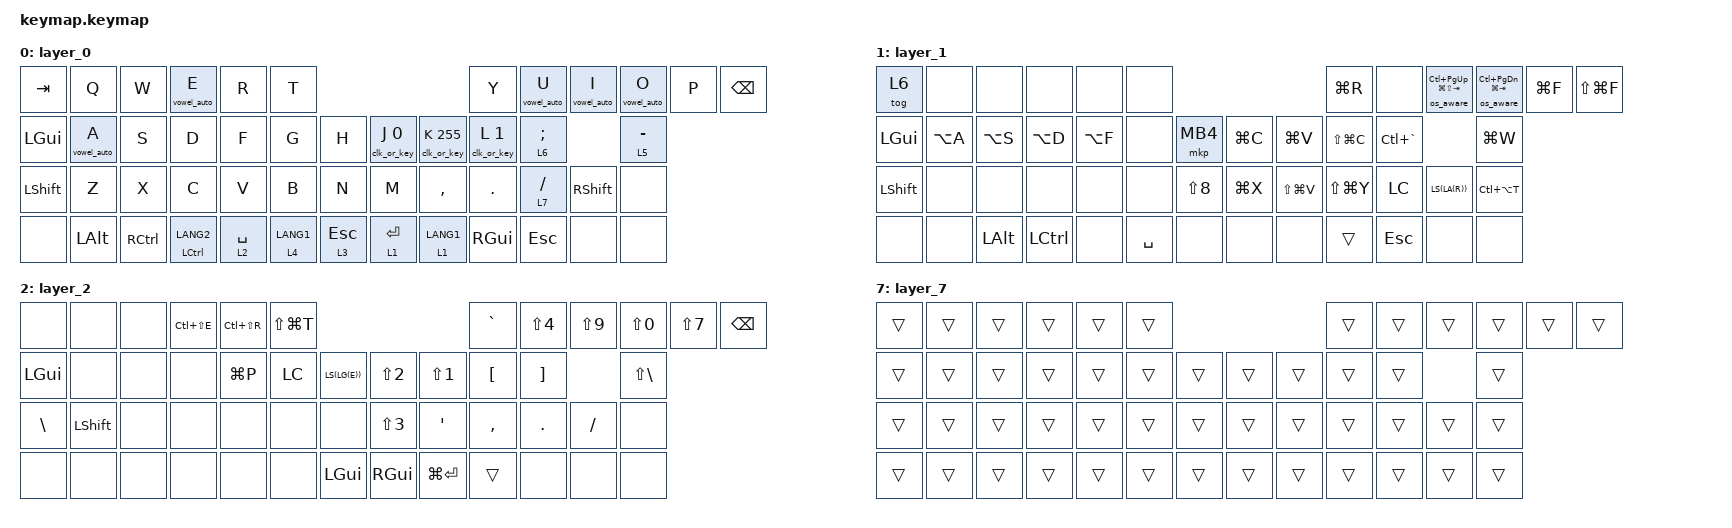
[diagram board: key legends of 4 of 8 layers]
/*
 * Copyright 2026 ren-mntn
 * SPDX-License-Identifier: MIT
 *
 * Ported from Keyball44 Remap keymap (7 layers).
 * Target: torabo-tsuki M variant (50 keys per layer: 12+12+12+14).
 */

#include <behaviors.dtsi>
#include <dt-bindings/zmk/bt.h>
#include <dt-bindings/zmk/keys.h>
#include <dt-bindings/zmk/mouse.h>
#include <dt-bindings/zmk/outputs.h>
#include <dt-bindings/zmk/pointing.h>

/ {
    behaviors {
        clk_or_key: clk_or_key {
            compatible = "zmk,behavior-clk-or-key";
            #binding-cells = <2>;
        };

        bt_toggle_01: bt_toggle_01 {
            compatible = "zmk,behavior-bt-toggle-01";
            #binding-cells = <0>;
        };

        vowel_auto: vowel_auto {
            compatible = "zmk,behavior-vowel-auto";
            #binding-cells = <1>;
        };

        os_aware: os_aware {
            compatible = "zmk,behavior-os-aware";
            #binding-cells = <2>;
        };
    };

    mouse_accel: mouse_accel {
        compatible = "zmk,input-processor-mouse-accel";
        #input-processor-cells = <0>;
    };

    scroll_mode: scroll_mode {
        compatible = "zmk,input-processor-scroll-mode";
        #input-processor-cells = <0>;
    };

    keymap {
        compatible = "zmk,keymap";

        /* Layer 0: Base QWERTY
         * Mouse-mode actions: J=LCLK, K=drag-scroll-trigger (0xFF), L=RCLK
         * Typing-mode fallback: J/K/L letters
         */
        layer_0 {
            bindings = <
&kp TAB    &kp Q      &kp W      &vowel_auto E &kp R      &kp T                                                &kp Y      &vowel_auto U      &vowel_auto I      &vowel_auto O      &kp P              &kp BSPC
&kp LGUI   &vowel_auto A &kp S   &kp D      &kp F      &kp G                                                   &kp H      &clk_or_key J 0  &clk_or_key K 255  &clk_or_key L 1  &lt 6 SEMI         &lt 5 MINUS
&kp LSHFT  &kp Z      &kp X      &kp C      &kp V      &kp B                                                   &kp N      &kp M              &kp COMMA          &kp DOT            &lt 7 FSLH         &kp RSHFT
&none      &none      &kp LALT   &kp RCTRL  &mt LCTRL LANG2  &lt 2 SPACE  &lt 4 LANG1           &lt 3 ESC  &lt 1 RET  &lt 1 LANG1        &kp RGUI           &kp ESC            &none              &none
            >;
        };

        /* Layer 1: Editor shortcuts (Win/Alt combos) */
        layer_1 {
            bindings = <
&tog 6     &none      &none      &none      &none      &none                                                   &kp LG(R)  &none              &os_aware LC(PG_UP) LG(LS(TAB))  &os_aware LC(PG_DN) LG(TAB)  &kp LG(F)          &kp LS(LG(F))
&kp LGUI   &kp LA(A)  &kp LA(S)  &kp LA(D)  &kp LA(F)  &none                                                   &mkp MB4   &kp LG(C)          &kp LG(V)          &kp LS(LG(C))      &kp LC(GRAVE)      &kp LG(W)
&kp LSHFT  &none      &none      &none      &none      &none                                                   &kp LS(N8) &kp LG(X)          &kp LS(LG(V))      &kp LS(LG(Y))      &kp LC(LS(LA(R)))  &kp LC(LA(T))
&none      &none      &kp LALT   &kp LCTRL  &none      &kp SPACE  &none                                 &none      &none              &trans             &kp ESC            &none              &none
            >;
        };

        /* Layer 2: Symbols */
        layer_2 {
            bindings = <
&none      &none      &none      &kp LC(LS(E)) &kp LC(LS(R)) &kp LS(LG(T))                                      &kp GRAVE  &kp LS(N4)         &kp LS(N9)         &kp LS(N0)         &kp LS(N7)         &kp BSPC
&kp LGUI   &none      &none      &none      &kp LG(P)  &kp LC(LS(LG(E)))                                        &kp LS(N2) &kp LS(N1)         &kp LBKT           &kp RBKT           &kp LS(BSLH)       &kp BSLH
&kp LSHFT  &none      &none      &none      &none      &none                                                   &kp LS(N3) &kp SQT            &kp COMMA          &kp DOT            &kp FSLH           &none
&none      &none      &none      &none      &none      &none      &kp LGUI                              &kp RGUI   &kp LG(RET)        &trans             &none              &none              &none
            >;
        };

        /* Layer 3: Neovim navigation (Ctrl combos) */
        layer_3 {
            bindings = <
&none      &none      &none      &none      &none      &none                                                   &none      &none              &none              &none              &none              &kp BSPC
&none      &none      &none      &none      &none      &none                                                   &kp LC(LS(E)) &kp LC(Q)       &kp LC(G)          &kp LC(GRAVE)      &kp LC(LS(GRAVE))  &none
&none      &none      &none      &none      &none      &none                                                   &kp LC(H)  &kp LC(J)          &kp LC(K)          &kp LC(L)          &none              &none
&none      &none      &none      &none      &none      &none      &kp LALT                              &none      &none              &trans             &none              &none              &none
            >;
        };

        /* Layer 4: Numbers */
        layer_4 {
            bindings = <
&none      &none      &none      &none      &none      &none                                                   &kp LS(COMMA) &kp LS(N5)      &kp EQUAL          &kp LS(EQUAL)      &kp LS(N8)         &kp BSPC
&kp LGUI   &none      &none      &none      &none      &none                                                   &kp N1     &kp N2             &kp N3             &kp N4             &kp N5             &kp MINUS
&kp LSHFT  &none      &none      &none      &none      &none                                                   &kp N6     &kp N7             &kp N8             &kp N9             &kp N0             &kp LS(SEMI)
&none      &none      &none      &kp LCTRL  &none      &kp SPACE  &none                                 &none      &none              &trans             &none              &none              &none
            >;
        };

        /* Layer 5: Window management / Screenshots
         * BT controls: MINUS-hold + Enter (right thumb second-from-left) = toggle profile 0<->1
         *              MINUS-hold + top-row left keys = explicit SEL/NXT/PRV/CLR
         */
        layer_5 {
            bindings = <
&bt BT_SEL 0 &bt BT_SEL 1 &bt BT_SEL 2 &bt BT_NXT &bt BT_PRV &bt BT_CLR                                          &kp LS(LG(N4))     &kp LC(LS(LG(N4))) &kp LC(LS(S))   &none             &kp LC(LS(LA(P)))  &none
&none      &none      &none      &none      &none      &none                                                   &kp LC(LS(LA(H)))  &kp LC(LS(LA(J)))  &kp LC(LS(LA(K))) &kp LC(LS(LA(L))) &kp LC(LS(LA(SEMI))) &none
&none      &none      &none      &none      &none      &none                                                   &kp LC(LS(LA(N)))  &kp LC(TAB)        &kp LA(TAB)    &none             &none              &none
&none      &none      &none      &none      &none      &none      &none                                 &none      &bt_toggle_01      &trans             &none              &none              &none
            >;
        };

        /* Layer 6: Gaming / Number row */
        layer_6 {
            bindings = <
&kp ESC    &kp TAB    &kp Q      &kp W      &kp E      &kp R                                                   &kp Y      &kp U              &kp I              &kp O              &tog 6             &kp DEL
&kp N1     &kp RCTRL  &kp A      &kp S      &kp D      &kp F                                                   &kp LEFT   &kp DOWN           &kp UP             &kp RIGHT          &kp F12            &kp HOME
&kp N2     &kp LSHFT  &kp Z      &kp X      &kp C      &kp V                                                   &kp N      &kp M              &kp GRAVE          &kp LBKT           &kp RBKT           &tog 6
&none      &none      &kp LGUI   &kp LALT   &kp N3     &kp SPACE  &kp N4                                &kp SPACE  &lt 1 RET          &trans             &kp ESC            &none              &none
            >;
        };

        /* Layer 7: Snipe Mode (low-CPI precise trackball)
         * Activated by holding FSLH ('・'). All keys are transparent
         * so other inputs fall through to layer 0; the pmw3610 driver
         * sees layer 7 as top-active and switches to CONFIG_PMW3610_SNIPE_CPI.
         */
        layer_7 {
            bindings = <
&trans     &trans     &trans     &trans     &trans     &trans                                                  &trans     &trans             &trans             &trans             &trans             &trans
&trans     &trans     &trans     &trans     &trans     &trans                                                  &trans     &trans             &trans             &trans             &trans             &trans
&trans     &trans     &trans     &trans     &trans     &trans                                                  &trans     &trans             &trans             &trans             &trans             &trans
&trans     &trans     &trans     &trans     &trans     &trans     &trans                                &trans     &trans             &trans             &trans             &trans             &trans             &trans
            >;
        };
    };
};
